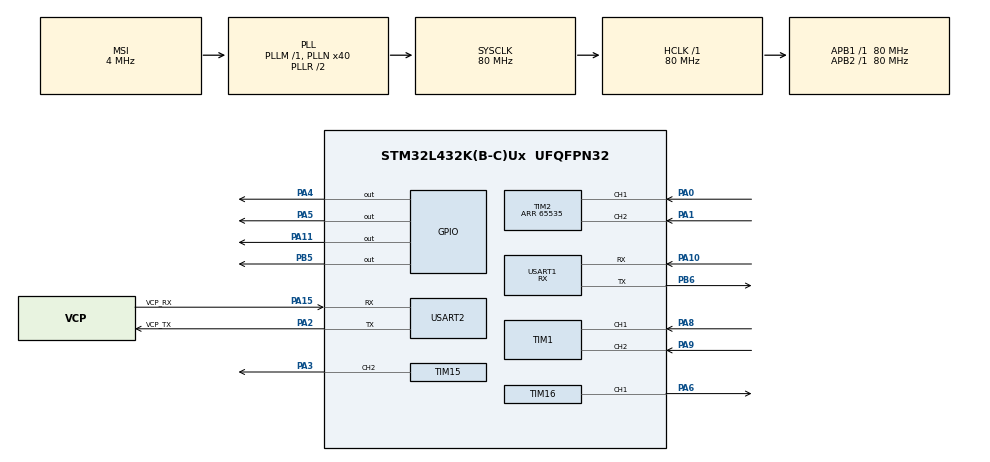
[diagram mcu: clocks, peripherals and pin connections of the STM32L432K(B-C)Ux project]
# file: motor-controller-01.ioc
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Dma.Request0=USART1_RX
Dma.USART1_RX.0.Direction=DMA_PERIPH_TO_MEMORY
Dma.USART1_RX.0.Instance=DMA1_Channel5
Dma.USART1_RX.0.MemDataAlignment=DMA_MDATAALIGN_BYTE
Dma.USART1_RX.0.MemInc=DMA_MINC_ENABLE
Dma.USART1_RX.0.Mode=DMA_CIRCULAR
Dma.USART1_RX.0.PeriphDataAlignment=DMA_PDATAALIGN_BYTE
Dma.USART1_RX.0.PeriphInc=DMA_PINC_DISABLE
Dma.USART1_RX.0.Priority=DMA_PRIORITY_LOW
Mcu.Family=STM32L4
Mcu.Name=STM32L432K(B-C)Ux
Mcu.Package=UFQFPN32
NVIC.DMA1_Channel5_IRQn=true\:0\:0\:false\:false\:true\:false\:true\:true
NVIC.PriorityGroup=NVIC_PRIORITYGROUP_4
PA0.Signal=S_TIM2_CH1
PA1.Signal=S_TIM2_CH2
PA10.Mode=Asynchronous
PA10.Signal=USART1_RX
PA11.Signal=GPIO_Output
PA13\ (JTMS-SWDIO).GPIO_Label=SWDIO
PA13\ (JTMS-SWDIO).Signal=SYS_JTMS-SWDIO
PA14\ (JTCK-SWCLK).GPIO_Label=SWCLK
PA14\ (JTCK-SWCLK).Signal=SYS_JTCK-SWCLK
PA15\ (JTDI).GPIO_Label=VCP_RX
PA15\ (JTDI).Mode=Asynchronous
PA15\ (JTDI).Signal=USART2_RX
PA2.GPIO_Label=VCP_TX
PA2.Mode=Asynchronous
PA2.Signal=USART2_TX
PA3.Signal=S_TIM15_CH2
PA4.Signal=GPIO_Output
PA5.Signal=GPIO_Output
PA6.Signal=S_TIM16_CH1
PA8.Signal=S_TIM1_CH1
PA9.Signal=S_TIM1_CH2
PB5.Signal=GPIO_Output
PB6.Mode=Asynchronous
PB6.Signal=USART1_TX
PC14-OSC32_IN\ (PC14).Signal=RCC_OSC32_IN
PC15-OSC32_OUT\ (PC15).Signal=RCC_OSC32_OUT
ProjectManager.HeapSize=0x200
ProjectManager.StackSize=0x400
ProjectManager.TargetToolchain=STM32CubeIDE
RCC.AHBFreq_Value=80000000
RCC.APB1Freq_Value=80000000
RCC.APB1TimFreq_Value=80000000
RCC.APB2Freq_Value=80000000
RCC.APB2TimFreq_Value=80000000
RCC.CortexFreq_Value=80000000
RCC.HCLKFreq_Value=80000000
RCC.HSE_VALUE=8000000
RCC.HSI16_VALUE=16000000
RCC.HSI48_VALUE=48000000
RCC.HSI_VALUE=16000000
RCC.LSE_VALUE=32768
RCC.MSI_VALUE=4000000
RCC.PLLMUL=RCC_PLLMUL_4
RCC.PLLN=40
RCC.SYSCLKFreq_VALUE=80000000
RCC.SYSCLKSource=RCC_SYSCLKSOURCE_PLLCLK
RCC.VCOOutputFreq_Value=160000000
SH.S_TIM15_CH2.0=TIM15_CH2,PWM Generation2 CH2
SH.S_TIM16_CH1.0=TIM16_CH1,PWM Generation1 CH1
SH.S_TIM1_CH1.0=TIM1_CH1,Encoder_Interface
SH.S_TIM1_CH2.0=TIM1_CH2,Encoder_Interface
SH.S_TIM2_CH1.0=TIM2_CH1,Encoder_Interface
SH.S_TIM2_CH2.0=TIM2_CH2,Encoder_Interface
TIM1.EncoderMode=TIM_ENCODERMODE_TI12
TIM15.Channel-PWM\ Generation2\ CH2=TIM_CHANNEL_2
TIM15.Period=1000
TIM15.Prescaler=2
TIM16.Channel=TIM_CHANNEL_1
TIM16.Period=1000
TIM16.Prescaler=2
TIM2.EncoderMode=TIM_ENCODERMODE_TI12
TIM2.Period=65535
USART1.Mode=MODE_RX
USART1.VirtualMode-Asynchronous=VM_ASYNC
USART2.VirtualMode-Asynchronous=VM_ASYNC
VP_TIM16_VS_ClockSourceINT.Mode=Enable_Timer
board=NUCLEO-L432KC

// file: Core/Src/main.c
/* USER CODE BEGIN Header */
/**
  ******************************************************************************
  * @file           : main.c
  * @brief          : Main program body
  ******************************************************************************
  * @attention
  *
  * Copyright (c) 2023 STMicroelectronics.
  * All rights reserved.
  *
  * This software is licensed under terms that can be found in the LICENSE file
  * in the root directory of this software component.
  * If no LICENSE file comes with this software, it is provided AS-IS.
  *
  ******************************************************************************
  */
/* USER CODE END Header */
#include "main.h"

/* USER CODE BEGIN Includes */
#include "app.h"
/* USER CODE END Includes */

TIM_HandleTypeDef htim1;
TIM_HandleTypeDef htim2;
TIM_HandleTypeDef htim15;
TIM_HandleTypeDef htim16;

UART_HandleTypeDef huart1;
UART_HandleTypeDef huart2;
DMA_HandleTypeDef hdma_usart1_rx;

void SystemClock_Config(void);
static void MX_GPIO_Init(void);
static void MX_DMA_Init(void);
static void MX_TIM15_Init(void);
static void MX_TIM16_Init(void);
static void MX_USART2_UART_Init(void);
static void MX_USART1_UART_Init(void);
static void MX_TIM1_Init(void);
static void MX_TIM2_Init(void);

int main(void)
{

  /* MCU Configuration--------------------------------------------------------*/

  /* Reset of all peripherals, Initializes the Flash interface and the Systick. */
  HAL_Init();

  /* Configure the system clock */
  SystemClock_Config();

  /* Initialize all configured peripherals */
  MX_GPIO_Init();
  MX_DMA_Init();
  MX_TIM15_Init();
  MX_TIM16_Init();
  MX_USART2_UART_Init();
  MX_USART1_UART_Init();
  MX_TIM1_Init();
  MX_TIM2_Init();
  /* USER CODE BEGIN 2 */
  app_init();
  /* USER CODE END 2 */

  /* Infinite loop */
  /* USER CODE BEGIN WHILE */
  while (1)
  {
	app_loop();
    /* USER CODE END WHILE */

  }
}

void SystemClock_Config(void)
{
  RCC_OscInitTypeDef RCC_OscInitStruct = {0};
  RCC_ClkInitTypeDef RCC_ClkInitStruct = {0};

  /** Configure the main internal regulator output voltage
  */
  if (HAL_PWREx_ControlVoltageScaling(PWR_REGULATOR_VOLTAGE_SCALE1) != HAL_OK)
  {
    Error_Handler();
  }

  /** Initializes the RCC Oscillators according to the specified parameters
  * in the RCC_OscInitTypeDef structure.
  */
  RCC_OscInitStruct.OscillatorType = RCC_OSCILLATORTYPE_MSI;
  RCC_OscInitStruct.MSIState = RCC_MSI_ON;
  RCC_OscInitStruct.MSICalibrationValue = 0;
  RCC_OscInitStruct.MSIClockRange = RCC_MSIRANGE_6;
  RCC_OscInitStruct.PLL.PLLState = RCC_PLL_ON;
  RCC_OscInitStruct.PLL.PLLSource = RCC_PLLSOURCE_MSI;
  RCC_OscInitStruct.PLL.PLLM = 1;
  RCC_OscInitStruct.PLL.PLLN = 40;
  RCC_OscInitStruct.PLL.PLLP = RCC_PLLP_DIV7;
  RCC_OscInitStruct.PLL.PLLQ = RCC_PLLQ_DIV2;
  RCC_OscInitStruct.PLL.PLLR = RCC_PLLR_DIV2;
  if (HAL_RCC_OscConfig(&RCC_OscInitStruct) != HAL_OK)
  {
    Error_Handler();
  }

  /** Initializes the CPU, AHB and APB buses clocks
  */
  RCC_ClkInitStruct.ClockType = RCC_CLOCKTYPE_HCLK|RCC_CLOCKTYPE_SYSCLK
                              |RCC_CLOCKTYPE_PCLK1|RCC_CLOCKTYPE_PCLK2;
  RCC_ClkInitStruct.SYSCLKSource = RCC_SYSCLKSOURCE_PLLCLK;
  RCC_ClkInitStruct.AHBCLKDivider = RCC_SYSCLK_DIV1;
  RCC_ClkInitStruct.APB1CLKDivider = RCC_HCLK_DIV1;
  RCC_ClkInitStruct.APB2CLKDivider = RCC_HCLK_DIV1;

  if (HAL_RCC_ClockConfig(&RCC_ClkInitStruct, FLASH_LATENCY_4) != HAL_OK)
  {
    Error_Handler();
  }
}

static void MX_TIM1_Init(void)
{

  TIM_Encoder_InitTypeDef sConfig = {0};
  TIM_MasterConfigTypeDef sMasterConfig = {0};

  htim1.Instance = TIM1;
  htim1.Init.Prescaler = 0;
  htim1.Init.CounterMode = TIM_COUNTERMODE_UP;
  htim1.Init.Period = 65535;
  htim1.Init.ClockDivision = TIM_CLOCKDIVISION_DIV1;
  htim1.Init.RepetitionCounter = 0;
  htim1.Init.AutoReloadPreload = TIM_AUTORELOAD_PRELOAD_DISABLE;
  sConfig.EncoderMode = TIM_ENCODERMODE_TI12;
  sConfig.IC1Polarity = TIM_ICPOLARITY_RISING;
  sConfig.IC1Selection = TIM_ICSELECTION_DIRECTTI;
  sConfig.IC1Prescaler = TIM_ICPSC_DIV1;
  sConfig.IC1Filter = 0;
  sConfig.IC2Polarity = TIM_ICPOLARITY_RISING;
  sConfig.IC2Selection = TIM_ICSELECTION_DIRECTTI;
  sConfig.IC2Prescaler = TIM_ICPSC_DIV1;
  sConfig.IC2Filter = 0;
  if (HAL_TIM_Encoder_Init(&htim1, &sConfig) != HAL_OK)
  {
    Error_Handler();
  }
  sMasterConfig.MasterOutputTrigger = TIM_TRGO_RESET;
  sMasterConfig.MasterOutputTrigger2 = TIM_TRGO2_RESET;
  sMasterConfig.MasterSlaveMode = TIM_MASTERSLAVEMODE_DISABLE;
  if (HAL_TIMEx_MasterConfigSynchronization(&htim1, &sMasterConfig) != HAL_OK)
  {
    Error_Handler();
  }

}

static void MX_TIM2_Init(void)
{

  TIM_Encoder_InitTypeDef sConfig = {0};
  TIM_MasterConfigTypeDef sMasterConfig = {0};

  htim2.Instance = TIM2;
  htim2.Init.Prescaler = 0;
  htim2.Init.CounterMode = TIM_COUNTERMODE_UP;
  htim2.Init.Period = 65535;
  htim2.Init.ClockDivision = TIM_CLOCKDIVISION_DIV1;
  htim2.Init.AutoReloadPreload = TIM_AUTORELOAD_PRELOAD_DISABLE;
  sConfig.EncoderMode = TIM_ENCODERMODE_TI12;
  sConfig.IC1Polarity = TIM_ICPOLARITY_RISING;
  sConfig.IC1Selection = TIM_ICSELECTION_DIRECTTI;
  sConfig.IC1Prescaler = TIM_ICPSC_DIV1;
  sConfig.IC1Filter = 0;
  sConfig.IC2Polarity = TIM_ICPOLARITY_RISING;
  sConfig.IC2Selection = TIM_ICSELECTION_DIRECTTI;
  sConfig.IC2Prescaler = TIM_ICPSC_DIV1;
  sConfig.IC2Filter = 0;
  if (HAL_TIM_Encoder_Init(&htim2, &sConfig) != HAL_OK)
  {
    Error_Handler();
  }
  sMasterConfig.MasterOutputTrigger = TIM_TRGO_RESET;
  sMasterConfig.MasterSlaveMode = TIM_MASTERSLAVEMODE_DISABLE;
  if (HAL_TIMEx_MasterConfigSynchronization(&htim2, &sMasterConfig) != HAL_OK)
  {
    Error_Handler();
  }

}

static void MX_TIM15_Init(void)
{

  TIM_MasterConfigTypeDef sMasterConfig = {0};
  TIM_OC_InitTypeDef sConfigOC = {0};
  TIM_BreakDeadTimeConfigTypeDef sBreakDeadTimeConfig = {0};

  htim15.Instance = TIM15;
  htim15.Init.Prescaler = 2;
  htim15.Init.CounterMode = TIM_COUNTERMODE_UP;
  htim15.Init.Period = 1000;
  htim15.Init.ClockDivision = TIM_CLOCKDIVISION_DIV1;
  htim15.Init.RepetitionCounter = 0;
  htim15.Init.AutoReloadPreload = TIM_AUTORELOAD_PRELOAD_DISABLE;
  if (HAL_TIM_PWM_Init(&htim15) != HAL_OK)
  {
    Error_Handler();
  }
  sMasterConfig.MasterOutputTrigger = TIM_TRGO_RESET;
  sMasterConfig.MasterSlaveMode = TIM_MASTERSLAVEMODE_DISABLE;
  if (HAL_TIMEx_MasterConfigSynchronization(&htim15, &sMasterConfig) != HAL_OK)
  {
    Error_Handler();
  }
  sConfigOC.OCMode = TIM_OCMODE_PWM1;
  sConfigOC.Pulse = 0;
  sConfigOC.OCPolarity = TIM_OCPOLARITY_HIGH;
  sConfigOC.OCNPolarity = TIM_OCNPOLARITY_HIGH;
  sConfigOC.OCFastMode = TIM_OCFAST_DISABLE;
  sConfigOC.OCIdleState = TIM_OCIDLESTATE_RESET;
  sConfigOC.OCNIdleState = TIM_OCNIDLESTATE_RESET;
  if (HAL_TIM_PWM_ConfigChannel(&htim15, &sConfigOC, TIM_CHANNEL_2) != HAL_OK)
  {
    Error_Handler();
  }
  sBreakDeadTimeConfig.OffStateRunMode = TIM_OSSR_DISABLE;
  sBreakDeadTimeConfig.OffStateIDLEMode = TIM_OSSI_DISABLE;
  sBreakDeadTimeConfig.LockLevel = TIM_LOCKLEVEL_OFF;
  sBreakDeadTimeConfig.DeadTime = 0;
  sBreakDeadTimeConfig.BreakState = TIM_BREAK_DISABLE;
  sBreakDeadTimeConfig.BreakPolarity = TIM_BREAKPOLARITY_HIGH;
  sBreakDeadTimeConfig.AutomaticOutput = TIM_AUTOMATICOUTPUT_DISABLE;
  if (HAL_TIMEx_ConfigBreakDeadTime(&htim15, &sBreakDeadTimeConfig) != HAL_OK)
  {
    Error_Handler();
  }
  HAL_TIM_MspPostInit(&htim15);

}

static void MX_TIM16_Init(void)
{

  TIM_OC_InitTypeDef sConfigOC = {0};
  TIM_BreakDeadTimeConfigTypeDef sBreakDeadTimeConfig = {0};

  htim16.Instance = TIM16;
  htim16.Init.Prescaler = 2;
  htim16.Init.CounterMode = TIM_COUNTERMODE_UP;
  htim16.Init.Period = 1000;
  htim16.Init.ClockDivision = TIM_CLOCKDIVISION_DIV1;
  htim16.Init.RepetitionCounter = 0;
  htim16.Init.AutoReloadPreload = TIM_AUTORELOAD_PRELOAD_DISABLE;
  if (HAL_TIM_Base_Init(&htim16) != HAL_OK)
  {
    Error_Handler();
  }
  if (HAL_TIM_PWM_Init(&htim16) != HAL_OK)
  {
    Error_Handler();
  }
  sConfigOC.OCMode = TIM_OCMODE_PWM1;
  sConfigOC.Pulse = 0;
  sConfigOC.OCPolarity = TIM_OCPOLARITY_HIGH;
  sConfigOC.OCNPolarity = TIM_OCNPOLARITY_HIGH;
  sConfigOC.OCFastMode = TIM_OCFAST_DISABLE;
  sConfigOC.OCIdleState = TIM_OCIDLESTATE_RESET;
  sConfigOC.OCNIdleState = TIM_OCNIDLESTATE_RESET;
  if (HAL_TIM_PWM_ConfigChannel(&htim16, &sConfigOC, TIM_CHANNEL_1) != HAL_OK)
  {
    Error_Handler();
  }
  sBreakDeadTimeConfig.OffStateRunMode = TIM_OSSR_DISABLE;
  sBreakDeadTimeConfig.OffStateIDLEMode = TIM_OSSI_DISABLE;
  sBreakDeadTimeConfig.LockLevel = TIM_LOCKLEVEL_OFF;
  sBreakDeadTimeConfig.DeadTime = 0;
  sBreakDeadTimeConfig.BreakState = TIM_BREAK_DISABLE;
  sBreakDeadTimeConfig.BreakPolarity = TIM_BREAKPOLARITY_HIGH;
  sBreakDeadTimeConfig.AutomaticOutput = TIM_AUTOMATICOUTPUT_DISABLE;
  if (HAL_TIMEx_ConfigBreakDeadTime(&htim16, &sBreakDeadTimeConfig) != HAL_OK)
  {
    Error_Handler();
  }
  HAL_TIM_MspPostInit(&htim16);

}

static void MX_USART1_UART_Init(void)
{

  huart1.Instance = USART1;
  huart1.Init.BaudRate = 115200;
  huart1.Init.WordLength = UART_WORDLENGTH_8B;
  huart1.Init.StopBits = UART_STOPBITS_1;
  huart1.Init.Parity = UART_PARITY_NONE;
  huart1.Init.Mode = UART_MODE_RX;
  huart1.Init.HwFlowCtl = UART_HWCONTROL_NONE;
  huart1.Init.OverSampling = UART_OVERSAMPLING_16;
  huart1.Init.OneBitSampling = UART_ONE_BIT_SAMPLE_DISABLE;
  huart1.AdvancedInit.AdvFeatureInit = UART_ADVFEATURE_NO_INIT;
  if (HAL_UART_Init(&huart1) != HAL_OK)
  {
    Error_Handler();
  }

}

static void MX_USART2_UART_Init(void)
{

  huart2.Instance = USART2;
  huart2.Init.BaudRate = 115200;
  huart2.Init.WordLength = UART_WORDLENGTH_8B;
  huart2.Init.StopBits = UART_STOPBITS_1;
  huart2.Init.Parity = UART_PARITY_NONE;
  huart2.Init.Mode = UART_MODE_TX_RX;
  huart2.Init.HwFlowCtl = UART_HWCONTROL_NONE;
  huart2.Init.OverSampling = UART_OVERSAMPLING_16;
  huart2.Init.OneBitSampling = UART_ONE_BIT_SAMPLE_DISABLE;
  huart2.AdvancedInit.AdvFeatureInit = UART_ADVFEATURE_NO_INIT;
  if (HAL_UART_Init(&huart2) != HAL_OK)
  {
    Error_Handler();
  }

}

static void MX_DMA_Init(void)
{

  /* DMA controller clock enable */
  __HAL_RCC_DMA1_CLK_ENABLE();

  /* DMA interrupt init */
  /* DMA1_Channel5_IRQn interrupt configuration */
  HAL_NVIC_SetPriority(DMA1_Channel5_IRQn, 0, 0);
  HAL_NVIC_EnableIRQ(DMA1_Channel5_IRQn);

}

static void MX_GPIO_Init(void)
{
  GPIO_InitTypeDef GPIO_InitStruct = {0};

  /* GPIO Ports Clock Enable */
  __HAL_RCC_GPIOC_CLK_ENABLE();
  __HAL_RCC_GPIOA_CLK_ENABLE();
  __HAL_RCC_GPIOB_CLK_ENABLE();

  /*Configure GPIO pin Output Level */
  HAL_GPIO_WritePin(GPIOA, GPIO_PIN_4|GPIO_PIN_5|GPIO_PIN_11, GPIO_PIN_RESET);

  /*Configure GPIO pin Output Level */
  HAL_GPIO_WritePin(GPIOB, GPIO_PIN_5, GPIO_PIN_RESET);

  /*Configure GPIO pins : PA4 PA5 PA11 */
  GPIO_InitStruct.Pin = GPIO_PIN_4|GPIO_PIN_5|GPIO_PIN_11;
  GPIO_InitStruct.Mode = GPIO_MODE_OUTPUT_PP;
  GPIO_InitStruct.Pull = GPIO_NOPULL;
  GPIO_InitStruct.Speed = GPIO_SPEED_FREQ_LOW;
  HAL_GPIO_Init(GPIOA, &GPIO_InitStruct);

  /*Configure GPIO pin : PB5 */
  GPIO_InitStruct.Pin = GPIO_PIN_5;
  GPIO_InitStruct.Mode = GPIO_MODE_OUTPUT_PP;
  GPIO_InitStruct.Pull = GPIO_NOPULL;
  GPIO_InitStruct.Speed = GPIO_SPEED_FREQ_LOW;
  HAL_GPIO_Init(GPIOB, &GPIO_InitStruct);

}

/* USER CODE BEGIN 4 */
// de-static the linkage to reset the UART
void
reset_uart(void)
{
	if (HAL_UART_DeInit(&huart1) != HAL_OK)
	{
		printf("Failed to deinit UART1\n");
	}
	MX_USART1_UART_Init();
}
/* USER CODE END 4 */

void Error_Handler(void)
{
  __disable_irq();
  while (1)
  {
  }
}
